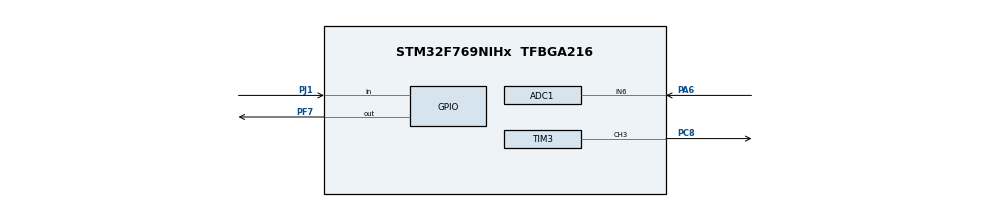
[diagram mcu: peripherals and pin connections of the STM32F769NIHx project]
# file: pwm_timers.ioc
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ADC1.Channel-0\#ChannelRegularConversion=ADC_CHANNEL_6
ADC1.NbrOfConversionFlag=1
ADC1.Rank-0\#ChannelRegularConversion=1
ADC1.SamplingTime-0\#ChannelRegularConversion=ADC_SAMPLETIME_144CYCLES
ADC1.master=1
Mcu.Family=STM32F7
Mcu.Name=STM32F769NIHx
Mcu.Package=TFBGA216
NVIC.ADC_IRQn=true\:0\:0\:false\:false\:true\:true\:true
NVIC.PriorityGroup=NVIC_PRIORITYGROUP_4
NVIC.TIM1_UP_TIM10_IRQn=true\:0\:0\:false\:false\:true\:true\:true
NVIC.TIM3_IRQn=true\:0\:0\:false\:false\:true\:true\:true
PA6.Signal=ADCx_IN6
PC8.Signal=S_TIM3_CH3
PF7.Signal=GPIO_Output
PJ1.Signal=GPIO_Input
ProjectManager.HeapSize=0x200
ProjectManager.StackSize=0x400
ProjectManager.TargetToolchain=STM32CubeIDE
RCC.HSE_VALUE=25000000
RCC.HSI_VALUE=16000000
RCC.LSE_VALUE=32768
RCC.USBFreq_Value=96000000
RCC.VCOOutputFreq_Value=192000000
SH.ADCx_IN6.0=ADC1_IN6,IN6
SH.S_TIM3_CH3.0=TIM3_CH3,PWM Generation3 CH3
TIM1.Period=1000
TIM1.Prescaler=800
TIM3.Channel-PWM\ Generation3\ CH3=TIM_CHANNEL_3
TIM3.Period=100
TIM3.Prescaler=8
TIM3.Pulse-PWM\ Generation3\ CH3=50
VP_TIM1_VS_ClockSourceINT.Mode=Internal
VP_TIM3_VS_ClockSourceINT.Mode=Internal
board=custom

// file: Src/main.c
/* USER CODE BEGIN Header */
/**
  ******************************************************************************
  * @file           : main.c
  * @brief          : Main program body
  ******************************************************************************
  * @attention
  *
  * <h2><center>&copy; Copyright (c) 2019 STMicroelectronics.
  * All rights reserved.</center></h2>
  *
  * This software component is licensed by ST under BSD 3-Clause license,
  * the "License"; You may not use this file except in compliance with the
  * License. You may obtain a copy of the License at:
  *                        opensource.org/licenses/BSD-3-Clause
  *
  ******************************************************************************
  */
/* USER CODE END Header */

#include "main.h"

ADC_HandleTypeDef hadc1;

TIM_HandleTypeDef htim1;
TIM_HandleTypeDef htim3;

/* USER CODE BEGIN PV */

volatile unsigned int *x,*y;
uint8_t dutycycle=50;
uint32_t adcResult = 0;
float intermediate=1.3;
/* USER CODE END PV */

void SystemClock_Config(void);
static void MX_GPIO_Init(void);
static void MX_TIM3_Init(void);
static void MX_TIM1_Init(void);
static void MX_ADC1_Init(void);

/* USER CODE BEGIN 0 */
#define ADC_MAX_VALUE                            4095
/* USER CODE END 0 */

int main(void)
{

  /* MCU Configuration--------------------------------------------------------*/

  /* Reset of all peripherals, Initializes the Flash interface and the Systick. */
  HAL_Init();

  /* Configure the system clock */
  SystemClock_Config();

  /* Initialize all configured peripherals */
  MX_GPIO_Init();
  MX_TIM3_Init();
  MX_TIM1_Init();
  MX_ADC1_Init();
  /* USER CODE BEGIN 2 */
HAL_TIM_Base_Start_IT(&htim3);
HAL_TIM_Base_Start_IT(&htim1);
HAL_TIM_PWM_Start(&htim3, TIM_CHANNEL_3);
HAL_ADC_Start_IT(&hadc1);

  /* USER CODE END 2 */

  /* Infinite loop */
  while (1)
  {
	  HAL_ADC_Start(&hadc1);

	      HAL_ADC_PollForConversion(&hadc1, 100);

	      adcResult = HAL_ADC_GetValue(&hadc1);

	      //scaling

	      //1 + 99 * (x - min(x)) / (max(x) - min(x))
          intermediate=((float)(adcResult-0)/(4095));
	      dutycycle=1+99*intermediate;
	      HAL_Delay(100);

  }
}

void SystemClock_Config(void)
{
  RCC_OscInitTypeDef RCC_OscInitStruct = {0};
  RCC_ClkInitTypeDef RCC_ClkInitStruct = {0};

  /** Configure the main internal regulator output voltage
  */
  __HAL_RCC_PWR_CLK_ENABLE();
  __HAL_PWR_VOLTAGESCALING_CONFIG(PWR_REGULATOR_VOLTAGE_SCALE3);
  /** Initializes the CPU, AHB and APB busses clocks
  */
  RCC_OscInitStruct.OscillatorType = RCC_OSCILLATORTYPE_HSI;
  RCC_OscInitStruct.HSIState = RCC_HSI_ON;
  RCC_OscInitStruct.HSICalibrationValue = RCC_HSICALIBRATION_DEFAULT;
  RCC_OscInitStruct.PLL.PLLState = RCC_PLL_NONE;
  if (HAL_RCC_OscConfig(&RCC_OscInitStruct) != HAL_OK)
  {
    Error_Handler();
  }
  /** Initializes the CPU, AHB and APB busses clocks
  */
  RCC_ClkInitStruct.ClockType = RCC_CLOCKTYPE_HCLK|RCC_CLOCKTYPE_SYSCLK
                              |RCC_CLOCKTYPE_PCLK1|RCC_CLOCKTYPE_PCLK2;
  RCC_ClkInitStruct.SYSCLKSource = RCC_SYSCLKSOURCE_HSI;
  RCC_ClkInitStruct.AHBCLKDivider = RCC_SYSCLK_DIV1;
  RCC_ClkInitStruct.APB1CLKDivider = RCC_HCLK_DIV1;
  RCC_ClkInitStruct.APB2CLKDivider = RCC_HCLK_DIV1;

  if (HAL_RCC_ClockConfig(&RCC_ClkInitStruct, FLASH_LATENCY_0) != HAL_OK)
  {
    Error_Handler();
  }
}

static void MX_ADC1_Init(void)
{

  ADC_ChannelConfTypeDef sConfig = {0};

  /** Configure the global features of the ADC (Clock, Resolution, Data Alignment and number of conversion)
  */
  hadc1.Instance = ADC1;
  hadc1.Init.ClockPrescaler = ADC_CLOCK_SYNC_PCLK_DIV2;
  hadc1.Init.Resolution = ADC_RESOLUTION_12B;
  hadc1.Init.ScanConvMode = DISABLE;
  hadc1.Init.ContinuousConvMode = DISABLE;
  hadc1.Init.DiscontinuousConvMode = DISABLE;
  hadc1.Init.ExternalTrigConvEdge = ADC_EXTERNALTRIGCONVEDGE_NONE;
  hadc1.Init.ExternalTrigConv = ADC_SOFTWARE_START;
  hadc1.Init.DataAlign = ADC_DATAALIGN_RIGHT;
  hadc1.Init.NbrOfConversion = 1;
  hadc1.Init.DMAContinuousRequests = DISABLE;
  hadc1.Init.EOCSelection = ADC_EOC_SINGLE_CONV;
  if (HAL_ADC_Init(&hadc1) != HAL_OK)
  {
    Error_Handler();
  }
  /** Configure for the selected ADC regular channel its corresponding rank in the sequencer and its sample time.
  */
  sConfig.Channel = ADC_CHANNEL_6;
  sConfig.Rank = ADC_REGULAR_RANK_1;
  sConfig.SamplingTime = ADC_SAMPLETIME_144CYCLES;
  if (HAL_ADC_ConfigChannel(&hadc1, &sConfig) != HAL_OK)
  {
    Error_Handler();
  }

}

static void MX_TIM1_Init(void)
{

  TIM_ClockConfigTypeDef sClockSourceConfig = {0};
  TIM_MasterConfigTypeDef sMasterConfig = {0};

  htim1.Instance = TIM1;
  htim1.Init.Prescaler = 800;
  htim1.Init.CounterMode = TIM_COUNTERMODE_UP;
  htim1.Init.Period = 1000;
  htim1.Init.ClockDivision = TIM_CLOCKDIVISION_DIV1;
  htim1.Init.RepetitionCounter = 0;
  htim1.Init.AutoReloadPreload = TIM_AUTORELOAD_PRELOAD_DISABLE;
  if (HAL_TIM_Base_Init(&htim1) != HAL_OK)
  {
    Error_Handler();
  }
  sClockSourceConfig.ClockSource = TIM_CLOCKSOURCE_INTERNAL;
  if (HAL_TIM_ConfigClockSource(&htim1, &sClockSourceConfig) != HAL_OK)
  {
    Error_Handler();
  }
  sMasterConfig.MasterOutputTrigger = TIM_TRGO_RESET;
  sMasterConfig.MasterOutputTrigger2 = TIM_TRGO2_RESET;
  sMasterConfig.MasterSlaveMode = TIM_MASTERSLAVEMODE_DISABLE;
  if (HAL_TIMEx_MasterConfigSynchronization(&htim1, &sMasterConfig) != HAL_OK)
  {
    Error_Handler();
  }

}

static void MX_TIM3_Init(void)
{

  TIM_ClockConfigTypeDef sClockSourceConfig = {0};
  TIM_MasterConfigTypeDef sMasterConfig = {0};
  TIM_OC_InitTypeDef sConfigOC = {0};

  htim3.Instance = TIM3;
  htim3.Init.Prescaler = 8;
  htim3.Init.CounterMode = TIM_COUNTERMODE_UP;
  htim3.Init.Period = 100;
  htim3.Init.ClockDivision = TIM_CLOCKDIVISION_DIV1;
  htim3.Init.AutoReloadPreload = TIM_AUTORELOAD_PRELOAD_DISABLE;
  if (HAL_TIM_Base_Init(&htim3) != HAL_OK)
  {
    Error_Handler();
  }
  sClockSourceConfig.ClockSource = TIM_CLOCKSOURCE_INTERNAL;
  if (HAL_TIM_ConfigClockSource(&htim3, &sClockSourceConfig) != HAL_OK)
  {
    Error_Handler();
  }
  if (HAL_TIM_PWM_Init(&htim3) != HAL_OK)
  {
    Error_Handler();
  }
  sMasterConfig.MasterOutputTrigger = TIM_TRGO_RESET;
  sMasterConfig.MasterSlaveMode = TIM_MASTERSLAVEMODE_DISABLE;
  if (HAL_TIMEx_MasterConfigSynchronization(&htim3, &sMasterConfig) != HAL_OK)
  {
    Error_Handler();
  }
  sConfigOC.OCMode = TIM_OCMODE_PWM1;
  sConfigOC.Pulse = 50;
  sConfigOC.OCPolarity = TIM_OCPOLARITY_HIGH;
  sConfigOC.OCFastMode = TIM_OCFAST_DISABLE;
  if (HAL_TIM_PWM_ConfigChannel(&htim3, &sConfigOC, TIM_CHANNEL_3) != HAL_OK)
  {
    Error_Handler();
  }
  HAL_TIM_MspPostInit(&htim3);

}

static void MX_GPIO_Init(void)
{
  GPIO_InitTypeDef GPIO_InitStruct = {0};

  /* GPIO Ports Clock Enable */
  __HAL_RCC_GPIOC_CLK_ENABLE();
  __HAL_RCC_GPIOF_CLK_ENABLE();
  __HAL_RCC_GPIOA_CLK_ENABLE();
  __HAL_RCC_GPIOJ_CLK_ENABLE();

  /*Configure GPIO pin Output Level */
  HAL_GPIO_WritePin(GPIOF, GPIO_PIN_7, GPIO_PIN_RESET);

  /*Configure GPIO pin : PF7 */
  GPIO_InitStruct.Pin = GPIO_PIN_7;
  GPIO_InitStruct.Mode = GPIO_MODE_OUTPUT_PP;
  GPIO_InitStruct.Pull = GPIO_NOPULL;
  GPIO_InitStruct.Speed = GPIO_SPEED_FREQ_LOW;
  HAL_GPIO_Init(GPIOF, &GPIO_InitStruct);

  /*Configure GPIO pin : PJ1 */
  GPIO_InitStruct.Pin = GPIO_PIN_1;
  GPIO_InitStruct.Mode = GPIO_MODE_INPUT;
  GPIO_InitStruct.Pull = GPIO_NOPULL;
  HAL_GPIO_Init(GPIOJ, &GPIO_InitStruct);

}

void Error_Handler(void)
{
}

/************************ (C) COPYRIGHT STMicroelectronics *****END OF FILE****/
